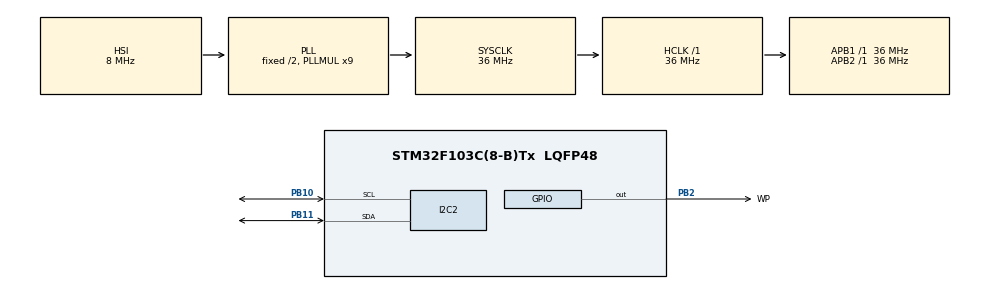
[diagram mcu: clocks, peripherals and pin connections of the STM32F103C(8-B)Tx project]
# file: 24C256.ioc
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IWDG.Prescaler=IWDG_PRESCALER_64
Mcu.Family=STM32F1
Mcu.Name=STM32F103C(8-B)Tx
Mcu.Package=LQFP48
NVIC.PriorityGroup=NVIC_PRIORITYGROUP_4
PA13.Mode=Serial_Wire
PA13.Signal=SYS_JTMS-SWDIO
PA14.Mode=Serial_Wire
PA14.Signal=SYS_JTCK-SWCLK
PB10.Mode=I2C
PB10.Signal=I2C2_SCL
PB11.Mode=I2C
PB11.Signal=I2C2_SDA
PB2.GPIO_Label=WP
PB2.GPIO_PuPd=GPIO_PULLDOWN
PB2.Signal=GPIO_Output
ProjectManager.HeapSize=0x400
ProjectManager.StackSize=0x800
ProjectManager.TargetToolchain=MDK-ARM V5.27
RCC.AHBFreq_Value=36000000
RCC.APB1Freq_Value=36000000
RCC.APB1TimFreq_Value=36000000
RCC.APB2Freq_Value=36000000
RCC.APB2TimFreq_Value=36000000
RCC.HCLKFreq_Value=36000000
RCC.PLLMUL=RCC_PLL_MUL9
RCC.SYSCLKFreq_VALUE=36000000
RCC.SYSCLKSource=RCC_SYSCLKSOURCE_PLLCLK
RCC.USBFreq_Value=36000000
VP_IWDG_VS_IWDG.Mode=IWDG_Activate
board=custom

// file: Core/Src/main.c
/* USER CODE BEGIN Header */
/**
  ******************************************************************************
  * @file           : main.c
  * @brief          : Main program body
  ******************************************************************************
  * @attention
  *
  * <h2><center>&copy; Copyright (c) 2021 STMicroelectronics.
  * All rights reserved.</center></h2>
  *
  * This software component is licensed by ST under BSD 3-Clause license,
  * the "License"; You may not use this file except in compliance with the
  * License. You may obtain a copy of the License at:
  *                        opensource.org/licenses/BSD-3-Clause
  *
  ******************************************************************************
  */
/* USER CODE END Header */
#include "main.h"
#include "i2c.h"
#include "iwdg.h"
#include "gpio.h"

/* USER CODE BEGIN Includes */
#include "at24cxx.h"

/* USER CODE END Includes */

/* USER CODE BEGIN PD */
#define MEM_ADDR    0x00u
/* USER CODE END PD */

/* USER CODE BEGIN PV */
bool writeStatus = false;
bool readStatus = false;
bool eraseStatus = false;
uint8_t  wData[] = "Hello World 123";
uint8_t  rData[25];

/* USER CODE END PV */

void SystemClock_Config(void);

int main(void)
{

  /* MCU Configuration--------------------------------------------------------*/

  /* Reset of all peripherals, Initializes the Flash interface and the Systick. */
  HAL_Init();

  /* Configure the system clock */
  SystemClock_Config();

  /* Initialize all configured peripherals */
  MX_GPIO_Init();
  MX_IWDG_Init();
  MX_I2C2_Init();
  /* USER CODE BEGIN 2 */
	// Refresh watchdog timer
	HAL_IWDG_Refresh(&hiwdg);

	if(at24_isConnected()){
		// at24_eraseChip can take more than 30 Sec
		eraseStatus = at24_eraseChip();
		HAL_Delay(10);
		writeStatus = at24_write(MEM_ADDR,wData, 15, 100);
		HAL_Delay(10);
		readStatus = at24_read(MEM_ADDR,rData, 15, 100);
		HAL_Delay(10);
	}

  /* USER CODE END 2 */

  /* Infinite loop */
  while (1)
  {

    /* USER CODE BEGIN 3 */
		HAL_IWDG_Refresh(&hiwdg);
  }
  /* USER CODE END 3 */
}

void SystemClock_Config(void)
{
  RCC_OscInitTypeDef RCC_OscInitStruct = {0};
  RCC_ClkInitTypeDef RCC_ClkInitStruct = {0};

  /** Initializes the RCC Oscillators according to the specified parameters
  * in the RCC_OscInitTypeDef structure.
  */
  RCC_OscInitStruct.OscillatorType = RCC_OSCILLATORTYPE_HSI|RCC_OSCILLATORTYPE_LSI;
  RCC_OscInitStruct.HSIState = RCC_HSI_ON;
  RCC_OscInitStruct.HSICalibrationValue = RCC_HSICALIBRATION_DEFAULT;
  RCC_OscInitStruct.LSIState = RCC_LSI_ON;
  RCC_OscInitStruct.PLL.PLLState = RCC_PLL_ON;
  RCC_OscInitStruct.PLL.PLLSource = RCC_PLLSOURCE_HSI_DIV2;
  RCC_OscInitStruct.PLL.PLLMUL = RCC_PLL_MUL9;
  if (HAL_RCC_OscConfig(&RCC_OscInitStruct) != HAL_OK)
  {
    Error_Handler();
  }
  /** Initializes the CPU, AHB and APB buses clocks
  */
  RCC_ClkInitStruct.ClockType = RCC_CLOCKTYPE_HCLK|RCC_CLOCKTYPE_SYSCLK
                              |RCC_CLOCKTYPE_PCLK1|RCC_CLOCKTYPE_PCLK2;
  RCC_ClkInitStruct.SYSCLKSource = RCC_SYSCLKSOURCE_PLLCLK;
  RCC_ClkInitStruct.AHBCLKDivider = RCC_SYSCLK_DIV1;
  RCC_ClkInitStruct.APB1CLKDivider = RCC_HCLK_DIV1;
  RCC_ClkInitStruct.APB2CLKDivider = RCC_HCLK_DIV1;

  if (HAL_RCC_ClockConfig(&RCC_ClkInitStruct, FLASH_LATENCY_1) != HAL_OK)
  {
    Error_Handler();
  }
}

void Error_Handler(void)
{
  __disable_irq();
  while (1)
  {
  }
}

/************************ (C) COPYRIGHT STMicroelectronics *****END OF FILE****/
